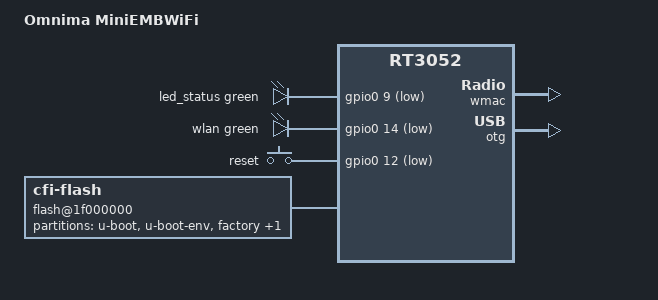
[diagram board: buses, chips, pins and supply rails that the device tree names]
#include "rt3050.dtsi"

#include <dt-bindings/gpio/gpio.h>
#include <dt-bindings/input/input.h>
#include <dt-bindings/leds/common.h>

/ {
	compatible = "omnima,miniembwifi", "ralink,rt3052-soc";
	model = "Omnima MiniEMBWiFi";

	aliases {
		led-boot = &led_status;
		led-failsafe = &led_status;
		led-running = &led_status;
		led-upgrade = &led_status;
	};

	leds {
		compatible = "gpio-leds";

		led_status: status {
			function = LED_FUNCTION_STATUS;
			color = <LED_COLOR_ID_GREEN>;
			gpios = <&gpio0 9 GPIO_ACTIVE_LOW>;
		};

		wlan {
			function = LED_FUNCTION_WLAN;
			color = <LED_COLOR_ID_GREEN>;
			gpios = <&gpio0 14 GPIO_ACTIVE_LOW>;
		};
	};

	keys {
		compatible = "gpio-keys-polled";
		poll-interval = <20>;

		reset {
			label = "reset";
			gpios = <&gpio0 12 GPIO_ACTIVE_LOW>;
			linux,code = <KEY_RESTART>;
		};
	};

	flash@1f000000 {
		compatible = "cfi-flash";
		reg = <0x1f000000 0x800000>;
		bank-width = <2>;
		device-width = <2>;

		partitions {
			compatible = "fixed-partitions";
			#address-cells = <1>;
			#size-cells = <1>;

			partition@0 {
				label = "u-boot";
				reg = <0x0 0x30000>;
				read-only;
			};

			partition@30000 {
				label = "u-boot-env";
				reg = <0x30000 0x10000>;
				read-only;
			};

			partition@40000 {
				label = "factory";
				reg = <0x40000 0x10000>;
				read-only;

				nvmem-layout {
					compatible = "fixed-layout";
					#address-cells = <1>;
					#size-cells = <1>;

					eeprom_factory_0: eeprom@0 {
						reg = <0x0 0x200>;
					};

					macaddr_factory_28: macaddr@28 {
						reg = <0x28 0x6>;
					};
				};
			};

			partition@50000 {
				compatible = "denx,uimage";
				label = "firmware";
				reg = <0x50000 0x7b0000>;
			};
		};
	};
};

&state_default {
	gpio {
		groups = "spi", "i2c", "jtag", "rgmii", "mdio", "uartf";
		function = "gpio";
	};
};

&ethernet {
	nvmem-cells = <&macaddr_factory_28>;
	nvmem-cell-names = "mac-address";
};

&esw {
	mediatek,portmap = <0x2f>;
};

&wmac {
	nvmem-cells = <&eeprom_factory_0>;
	nvmem-cell-names = "eeprom";
};

&otg {
	status = "okay";
};
